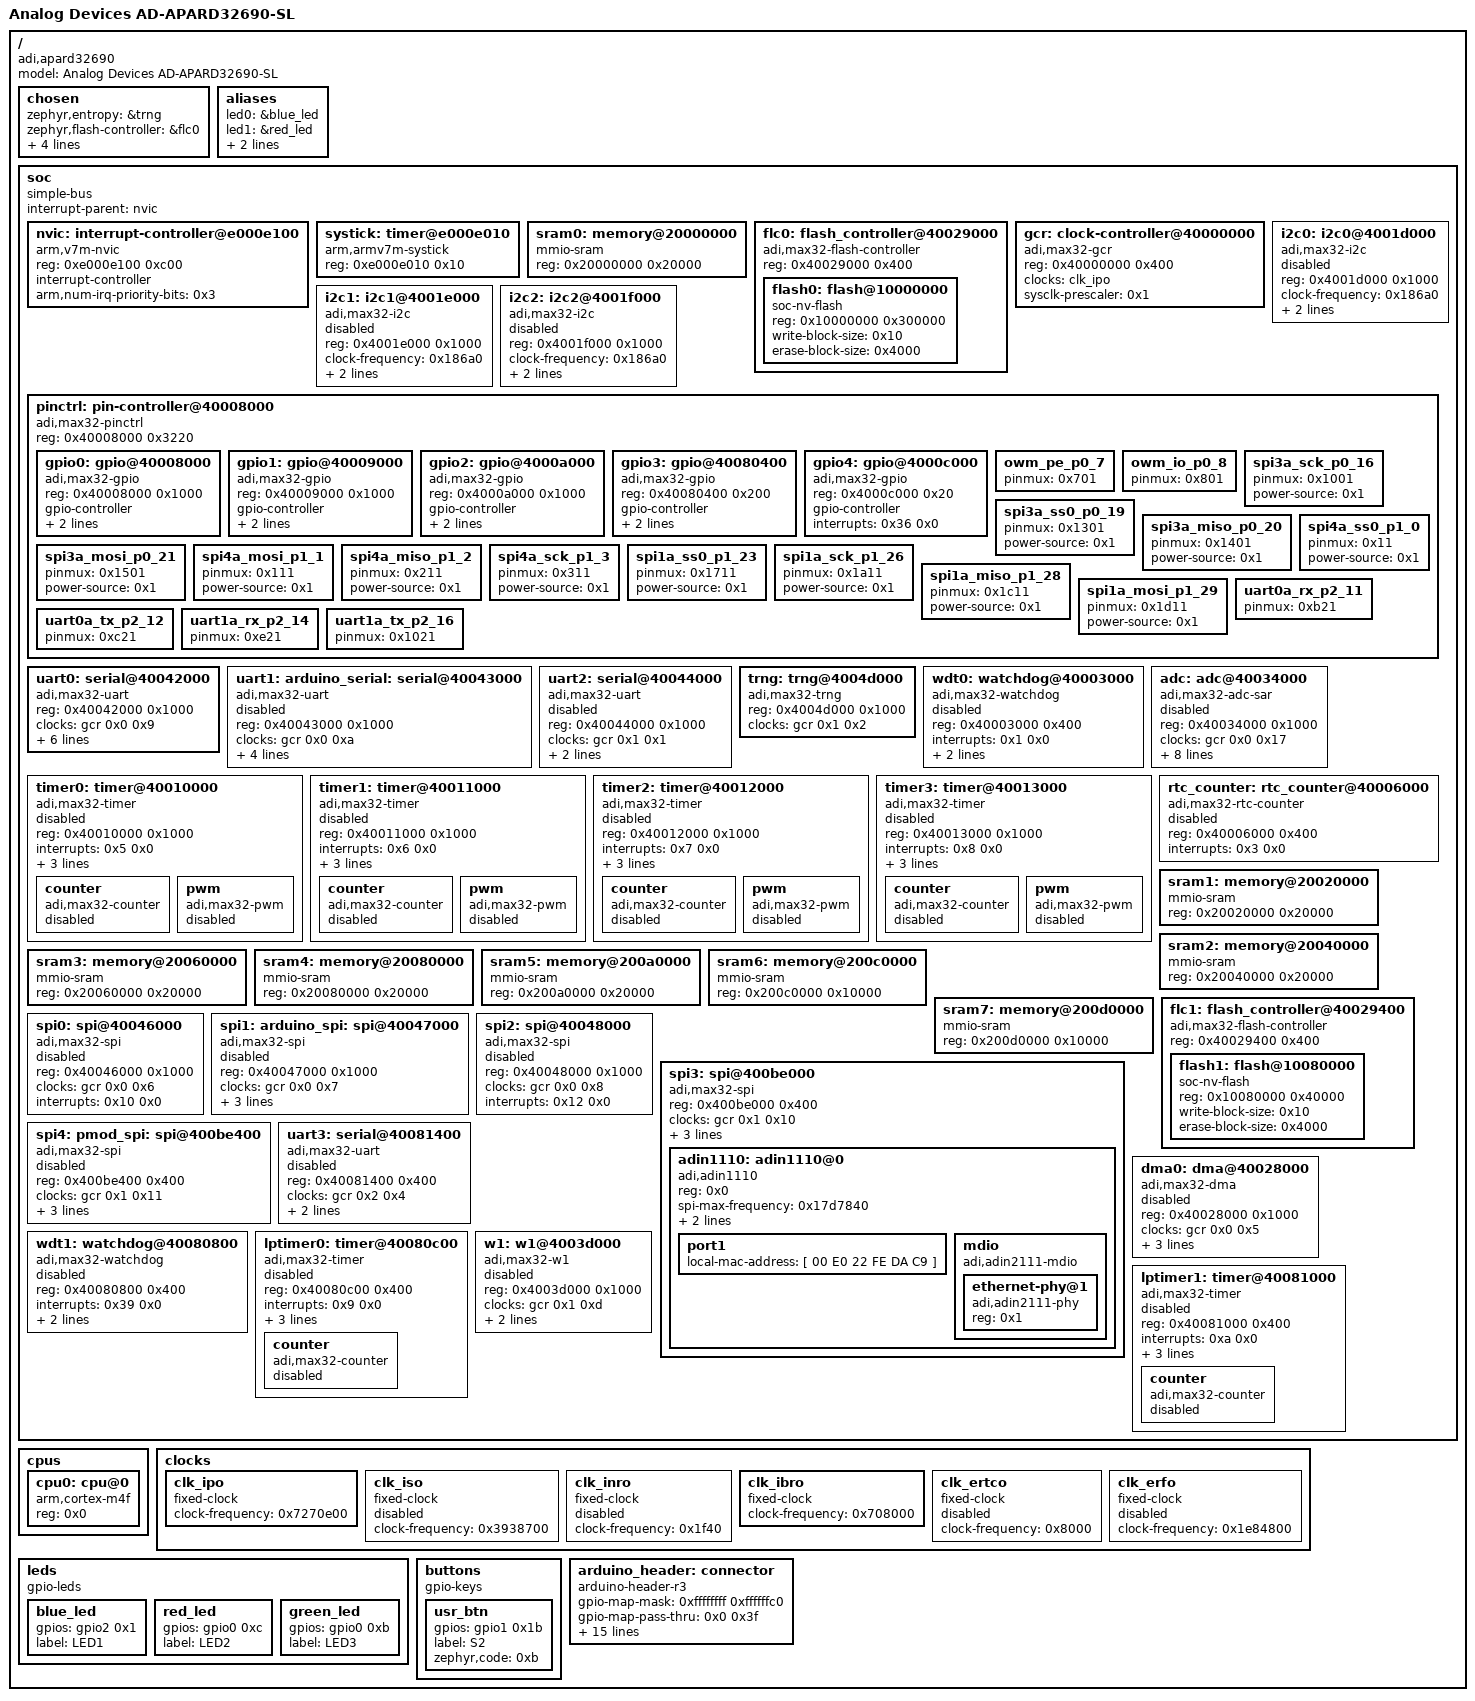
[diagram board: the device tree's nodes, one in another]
/dts-v1/;

/ {
	#address-cells = < 0x1 >;
	#size-cells = < 0x1 >;
	model = "Analog Devices AD-APARD32690-SL";
	compatible = "adi,apard32690";
	chosen {
		zephyr,entropy = &trng;
		zephyr,flash-controller = &flc0;
		zephyr,console = &uart0;
		zephyr,shell-uart = &uart0;
		zephyr,sram = &sram0;
		zephyr,flash = &flash0;
	};
	aliases {
		led0 = &blue_led;
		led1 = &red_led;
		led2 = &green_led;
		sw0 = &usr_btn;
	};
	soc {
		#address-cells = < 0x1 >;
		#size-cells = < 0x1 >;
		compatible = "simple-bus";
		interrupt-parent = < &nvic >;
		ranges;
		nvic: interrupt-controller@e000e100 {
			#address-cells = < 0x1 >;
			compatible = "arm,v7m-nvic";
			reg = < 0xe000e100 0xc00 >;
			interrupt-controller;
			#interrupt-cells = < 0x2 >;
			arm,num-irq-priority-bits = < 0x3 >;
			phandle = < 0x1 >;
		};
		systick: timer@e000e010 {
			compatible = "arm,armv7m-systick";
			reg = < 0xe000e010 0x10 >;
		};
		sram0: memory@20000000 {
			compatible = "mmio-sram";
			reg = < 0x20000000 0x20000 >;
		};
		flc0: flash_controller@40029000 {
			compatible = "adi,max32-flash-controller";
			reg = < 0x40029000 0x400 >;
			#address-cells = < 0x1 >;
			#size-cells = < 0x1 >;
			status = "okay";
			flash0: flash@10000000 {
				compatible = "soc-nv-flash";
				reg = < 0x10000000 0x300000 >;
				write-block-size = < 0x10 >;
				erase-block-size = < 0x4000 >;
			};
		};
		gcr: clock-controller@40000000 {
			reg = < 0x40000000 0x400 >;
			compatible = "adi,max32-gcr";
			#clock-cells = < 0x2 >;
			clocks = < &clk_ipo >;
			sysclk-prescaler = < 0x1 >;
			status = "okay";
			phandle = < 0x3 >;
		};
		i2c0: i2c0@4001d000 {
			compatible = "adi,max32-i2c";
			reg = < 0x4001d000 0x1000 >;
			#address-cells = < 0x1 >;
			#size-cells = < 0x0 >;
			clock-frequency = < 0x186a0 >;
			clocks = < &gcr 0x0 0xd >;
			interrupts = < 0xd 0x0 >;
			status = "disabled";
		};
		i2c1: i2c1@4001e000 {
			compatible = "adi,max32-i2c";
			reg = < 0x4001e000 0x1000 >;
			#address-cells = < 0x1 >;
			#size-cells = < 0x0 >;
			clock-frequency = < 0x186a0 >;
			clocks = < &gcr 0x0 0x1c >;
			interrupts = < 0x24 0x0 >;
			status = "disabled";
		};
		i2c2: i2c2@4001f000 {
			compatible = "adi,max32-i2c";
			reg = < 0x4001f000 0x1000 >;
			#address-cells = < 0x1 >;
			#size-cells = < 0x0 >;
			clock-frequency = < 0x186a0 >;
			clocks = < &gcr 0x1 0x18 >;
			interrupts = < 0x3e 0x0 >;
			status = "disabled";
		};
		pinctrl: pin-controller@40008000 {
			compatible = "adi,max32-pinctrl";
			#address-cells = < 0x1 >;
			#size-cells = < 0x1 >;
			reg = < 0x40008000 0x3220 >;
			gpio0: gpio@40008000 {
				reg = < 0x40008000 0x1000 >;
				compatible = "adi,max32-gpio";
				gpio-controller;
				#gpio-cells = < 0x2 >;
				clocks = < &gcr 0x0 0x0 >;
				interrupts = < 0x18 0x0 >;
				status = "okay";
				phandle = < 0x10 >;
			};
			gpio1: gpio@40009000 {
				reg = < 0x40009000 0x1000 >;
				compatible = "adi,max32-gpio";
				gpio-controller;
				#gpio-cells = < 0x2 >;
				interrupts = < 0x19 0x0 >;
				clocks = < &gcr 0x0 0x1 >;
				status = "okay";
				phandle = < 0x18 >;
			};
			gpio2: gpio@4000a000 {
				reg = < 0x4000a000 0x1000 >;
				compatible = "adi,max32-gpio";
				gpio-controller;
				#gpio-cells = < 0x2 >;
				interrupts = < 0x1a 0x0 >;
				clocks = < &gcr 0x0 0x2 >;
				status = "okay";
				phandle = < 0x17 >;
			};
			gpio3: gpio@40080400 {
				reg = < 0x40080400 0x200 >;
				compatible = "adi,max32-gpio";
				gpio-controller;
				#gpio-cells = < 0x2 >;
				interrupts = < 0x3a 0x0 >;
				clocks = < &gcr 0x2 0x0 >;
				status = "okay";
				phandle = < 0x19 >;
			};
			gpio4: gpio@4000c000 {
				reg = < 0x4000c000 0x20 >;
				compatible = "adi,max32-gpio";
				gpio-controller;
				#gpio-cells = < 0x2 >;
				interrupts = < 0x36 0x0 >;
				status = "okay";
			};
			owm_pe_p0_7: owm_pe_p0_7 {
				pinmux = < 0x701 >;
				phandle = < 0x16 >;
			};
			owm_io_p0_8: owm_io_p0_8 {
				pinmux = < 0x801 >;
				phandle = < 0x15 >;
			};
			spi3a_sck_p0_16: spi3a_sck_p0_16 {
				pinmux = < 0x1001 >;
				power-source = < 0x1 >;
				phandle = < 0xe >;
			};
			spi3a_ss0_p0_19: spi3a_ss0_p0_19 {
				pinmux = < 0x1301 >;
				power-source = < 0x1 >;
				phandle = < 0xf >;
			};
			spi3a_miso_p0_20: spi3a_miso_p0_20 {
				pinmux = < 0x1401 >;
				power-source = < 0x1 >;
				phandle = < 0xc >;
			};
			spi3a_mosi_p0_21: spi3a_mosi_p0_21 {
				pinmux = < 0x1501 >;
				power-source = < 0x1 >;
				phandle = < 0xd >;
			};
			spi4a_ss0_p1_0: spi4a_ss0_p1_0 {
				pinmux = < 0x11 >;
				power-source = < 0x1 >;
				phandle = < 0x14 >;
			};
			spi4a_mosi_p1_1: spi4a_mosi_p1_1 {
				pinmux = < 0x111 >;
				power-source = < 0x1 >;
				phandle = < 0x12 >;
			};
			spi4a_miso_p1_2: spi4a_miso_p1_2 {
				pinmux = < 0x211 >;
				power-source = < 0x1 >;
				phandle = < 0x11 >;
			};
			spi4a_sck_p1_3: spi4a_sck_p1_3 {
				pinmux = < 0x311 >;
				power-source = < 0x1 >;
				phandle = < 0x13 >;
			};
			spi1a_ss0_p1_23: spi1a_ss0_p1_23 {
				pinmux = < 0x1711 >;
				power-source = < 0x1 >;
				phandle = < 0xb >;
			};
			spi1a_sck_p1_26: spi1a_sck_p1_26 {
				pinmux = < 0x1a11 >;
				power-source = < 0x1 >;
				phandle = < 0xa >;
			};
			spi1a_miso_p1_28: spi1a_miso_p1_28 {
				pinmux = < 0x1c11 >;
				power-source = < 0x1 >;
				phandle = < 0x8 >;
			};
			spi1a_mosi_p1_29: spi1a_mosi_p1_29 {
				pinmux = < 0x1d11 >;
				power-source = < 0x1 >;
				phandle = < 0x9 >;
			};
			uart0a_rx_p2_11: uart0a_rx_p2_11 {
				pinmux = < 0xb21 >;
				phandle = < 0x5 >;
			};
			uart0a_tx_p2_12: uart0a_tx_p2_12 {
				pinmux = < 0xc21 >;
				phandle = < 0x4 >;
			};
			uart1a_rx_p2_14: uart1a_rx_p2_14 {
				pinmux = < 0xe21 >;
				phandle = < 0x7 >;
			};
			uart1a_tx_p2_16: uart1a_tx_p2_16 {
				pinmux = < 0x1021 >;
				phandle = < 0x6 >;
			};
		};
		uart0: serial@40042000 {
			compatible = "adi,max32-uart";
			reg = < 0x40042000 0x1000 >;
			clocks = < &gcr 0x0 0x9 >;
			clock-source = < 0x2 >;
			interrupts = < 0xe 0x0 >;
			status = "okay";
			pinctrl-0 = < &uart0a_tx_p2_12 &uart0a_rx_p2_11 >;
			pinctrl-names = "default";
			current-speed = < 0x1c200 >;
			data-bits = < 0x8 >;
			parity = "none";
		};
		uart1: arduino_serial: serial@40043000 {
			compatible = "adi,max32-uart";
			reg = < 0x40043000 0x1000 >;
			clocks = < &gcr 0x0 0xa >;
			clock-source = < 0x2 >;
			interrupts = < 0xf 0x0 >;
			status = "disabled";
			pinctrl-0 = < &uart1a_tx_p2_16 &uart1a_rx_p2_14 >;
			pinctrl-names = "default";
			current-speed = < 0x1c200 >;
		};
		uart2: serial@40044000 {
			compatible = "adi,max32-uart";
			reg = < 0x40044000 0x1000 >;
			clocks = < &gcr 0x1 0x1 >;
			clock-source = < 0x0 >;
			interrupts = < 0x22 0x0 >;
			status = "disabled";
		};
		trng: trng@4004d000 {
			compatible = "adi,max32-trng";
			reg = < 0x4004d000 0x1000 >;
			clocks = < &gcr 0x1 0x2 >;
			status = "okay";
		};
		wdt0: watchdog@40003000 {
			compatible = "adi,max32-watchdog";
			reg = < 0x40003000 0x400 >;
			interrupts = < 0x1 0x0 >;
			clocks = < &gcr 0x1 0x1b >;
			clock-source = < 0x0 >;
			status = "disabled";
		};
		adc: adc@40034000 {
			compatible = "adi,max32-adc-sar", "adi,max32-adc";
			reg = < 0x40034000 0x1000 >;
			clocks = < &gcr 0x0 0x17 >;
			channel-count = < 0x15 >;
			#io-channel-cells = < 0x1 >;
			interrupts = < 0x14 0x0 >;
			resolution = < 0xc >;
			vref-mv = < 0x4e2 >;
			status = "disabled";
			clock-source = < 0x0 >;
			clock-divider = < 0x10 >;
			track-count = < 0x4 >;
			idle-count = < 0x5 >;
		};
		timer0: timer@40010000 {
			compatible = "adi,max32-timer";
			reg = < 0x40010000 0x1000 >;
			interrupts = < 0x5 0x0 >;
			status = "disabled";
			clocks = < &gcr 0x0 0xf >;
			clock-source = < 0x0 >;
			prescaler = < 0x1 >;
			counter {
				compatible = "adi,max32-counter";
				status = "disabled";
			};
			pwm {
				compatible = "adi,max32-pwm";
				status = "disabled";
				#pwm-cells = < 0x3 >;
			};
		};
		timer1: timer@40011000 {
			compatible = "adi,max32-timer";
			reg = < 0x40011000 0x1000 >;
			interrupts = < 0x6 0x0 >;
			status = "disabled";
			clocks = < &gcr 0x0 0x10 >;
			clock-source = < 0x0 >;
			prescaler = < 0x1 >;
			counter {
				compatible = "adi,max32-counter";
				status = "disabled";
			};
			pwm {
				compatible = "adi,max32-pwm";
				status = "disabled";
				#pwm-cells = < 0x3 >;
			};
		};
		timer2: timer@40012000 {
			compatible = "adi,max32-timer";
			reg = < 0x40012000 0x1000 >;
			interrupts = < 0x7 0x0 >;
			status = "disabled";
			clocks = < &gcr 0x0 0x11 >;
			clock-source = < 0x0 >;
			prescaler = < 0x1 >;
			counter {
				compatible = "adi,max32-counter";
				status = "disabled";
			};
			pwm {
				compatible = "adi,max32-pwm";
				status = "disabled";
				#pwm-cells = < 0x3 >;
			};
		};
		timer3: timer@40013000 {
			compatible = "adi,max32-timer";
			reg = < 0x40013000 0x1000 >;
			interrupts = < 0x8 0x0 >;
			status = "disabled";
			clocks = < &gcr 0x0 0x12 >;
			clock-source = < 0x0 >;
			prescaler = < 0x1 >;
			counter {
				compatible = "adi,max32-counter";
				status = "disabled";
			};
			pwm {
				compatible = "adi,max32-pwm";
				status = "disabled";
				#pwm-cells = < 0x3 >;
			};
		};
		rtc_counter: rtc_counter@40006000 {
			compatible = "adi,max32-rtc-counter";
			reg = < 0x40006000 0x400 >;
			interrupts = < 0x3 0x0 >;
			status = "disabled";
		};
		sram1: memory@20020000 {
			compatible = "mmio-sram";
			reg = < 0x20020000 0x20000 >;
		};
		sram2: memory@20040000 {
			compatible = "mmio-sram";
			reg = < 0x20040000 0x20000 >;
		};
		sram3: memory@20060000 {
			compatible = "mmio-sram";
			reg = < 0x20060000 0x20000 >;
		};
		sram4: memory@20080000 {
			compatible = "mmio-sram";
			reg = < 0x20080000 0x20000 >;
		};
		sram5: memory@200a0000 {
			compatible = "mmio-sram";
			reg = < 0x200a0000 0x20000 >;
		};
		sram6: memory@200c0000 {
			compatible = "mmio-sram";
			reg = < 0x200c0000 0x10000 >;
		};
		sram7: memory@200d0000 {
			compatible = "mmio-sram";
			reg = < 0x200d0000 0x10000 >;
		};
		flc1: flash_controller@40029400 {
			compatible = "adi,max32-flash-controller";
			reg = < 0x40029400 0x400 >;
			#address-cells = < 0x1 >;
			#size-cells = < 0x1 >;
			status = "okay";
			flash1: flash@10080000 {
				compatible = "soc-nv-flash";
				reg = < 0x10080000 0x40000 >;
				write-block-size = < 0x10 >;
				erase-block-size = < 0x4000 >;
			};
		};
		spi0: spi@40046000 {
			compatible = "adi,max32-spi";
			reg = < 0x40046000 0x1000 >;
			#address-cells = < 0x1 >;
			#size-cells = < 0x0 >;
			clocks = < &gcr 0x0 0x6 >;
			interrupts = < 0x10 0x0 >;
			status = "disabled";
		};
		spi1: arduino_spi: spi@40047000 {
			compatible = "adi,max32-spi";
			reg = < 0x40047000 0x1000 >;
			#address-cells = < 0x1 >;
			#size-cells = < 0x0 >;
			clocks = < &gcr 0x0 0x7 >;
			interrupts = < 0x11 0x0 >;
			status = "disabled";
			pinctrl-0 = < &spi1a_miso_p1_28 &spi1a_mosi_p1_29 &spi1a_sck_p1_26 &spi1a_ss0_p1_23 >;
			pinctrl-names = "default";
		};
		spi2: spi@40048000 {
			compatible = "adi,max32-spi";
			reg = < 0x40048000 0x1000 >;
			#address-cells = < 0x1 >;
			#size-cells = < 0x0 >;
			clocks = < &gcr 0x0 0x8 >;
			interrupts = < 0x12 0x0 >;
			status = "disabled";
		};
		spi3: spi@400be000 {
			compatible = "adi,max32-spi";
			reg = < 0x400be000 0x400 >;
			#address-cells = < 0x1 >;
			#size-cells = < 0x0 >;
			clocks = < &gcr 0x1 0x10 >;
			interrupts = < 0x38 0x0 >;
			status = "okay";
			pinctrl-0 = < &spi3a_miso_p0_20 &spi3a_mosi_p0_21 &spi3a_sck_p0_16 &spi3a_ss0_p0_19 >;
			pinctrl-names = "default";
			adin1110: adin1110@0 {
				compatible = "adi,adin1110";
				reg = < 0x0 >;
				spi-max-frequency = < 0x17d7840 >;
				int-gpios = < &gpio0 0x11 0x101 >;
				reset-gpios = < &gpio0 0xf 0x101 >;
				status = "okay";
				port1 {
					local-mac-address = [ 00 E0 22 FE DA C9 ];
				};
				mdio {
					compatible = "adi,adin2111-mdio";
					#address-cells = < 0x1 >;
					#size-cells = < 0x0 >;
					ethernet-phy@1 {
						reg = < 0x1 >;
						compatible = "adi,adin2111-phy";
					};
				};
			};
		};
		spi4: pmod_spi: spi@400be400 {
			compatible = "adi,max32-spi";
			reg = < 0x400be400 0x400 >;
			#address-cells = < 0x1 >;
			#size-cells = < 0x0 >;
			clocks = < &gcr 0x1 0x11 >;
			interrupts = < 0x69 0x0 >;
			status = "disabled";
			pinctrl-0 = < &spi4a_miso_p1_2 &spi4a_mosi_p1_1 &spi4a_sck_p1_3 &spi4a_ss0_p1_0 >;
			pinctrl-names = "default";
		};
		uart3: serial@40081400 {
			compatible = "adi,max32-uart";
			reg = < 0x40081400 0x400 >;
			clocks = < &gcr 0x2 0x4 >;
			clock-source = < 0x2 >;
			interrupts = < 0x58 0x0 >;
			status = "disabled";
		};
		dma0: dma@40028000 {
			compatible = "adi,max32-dma";
			reg = < 0x40028000 0x1000 >;
			clocks = < &gcr 0x0 0x5 >;
			interrupts = < 0x1c 0x0 >, < 0x1d 0x0 >, < 0x1e 0x0 >, < 0x1f 0x0 >;
			dma-channels = < 0x10 >;
			status = "disabled";
			#dma-cells = < 0x2 >;
		};
		wdt1: watchdog@40080800 {
			compatible = "adi,max32-watchdog";
			reg = < 0x40080800 0x400 >;
			interrupts = < 0x39 0x0 >;
			clocks = < &gcr 0x2 0x1 >;
			clock-source = < 0x2 >;
			status = "disabled";
		};
		lptimer0: timer@40080c00 {
			compatible = "adi,max32-timer";
			reg = < 0x40080c00 0x400 >;
			interrupts = < 0x9 0x0 >;
			status = "disabled";
			clocks = < &gcr 0x2 0x2 >;
			clock-source = < 0x2 >;
			prescaler = < 0x1 >;
			counter {
				compatible = "adi,max32-counter";
				status = "disabled";
			};
		};
		lptimer1: timer@40081000 {
			compatible = "adi,max32-timer";
			reg = < 0x40081000 0x400 >;
			interrupts = < 0xa 0x0 >;
			status = "disabled";
			clocks = < &gcr 0x2 0x3 >;
			clock-source = < 0x2 >;
			prescaler = < 0x1 >;
			counter {
				compatible = "adi,max32-counter";
				status = "disabled";
			};
		};
		w1: w1@4003d000 {
			compatible = "adi,max32-w1";
			reg = < 0x4003d000 0x1000 >;
			clocks = < &gcr 0x1 0xd >;
			interrupts = < 0x43 0x0 >;
			status = "disabled";
			pinctrl-0 = < &owm_io_p0_8 &owm_pe_p0_7 >;
			pinctrl-names = "default";
		};
	};
	cpus {
		#address-cells = < 0x1 >;
		#size-cells = < 0x0 >;
		cpu0: cpu@0 {
			device_type = "cpu";
			compatible = "arm,cortex-m4f";
			reg = < 0x0 >;
		};
	};
	clocks {
		clk_ipo: clk_ipo {
			compatible = "fixed-clock";
			#clock-cells = < 0x0 >;
			clock-frequency = < 0x7270e00 >;
			status = "okay";
			phandle = < 0x2 >;
		};
		clk_iso: clk_iso {
			compatible = "fixed-clock";
			#clock-cells = < 0x0 >;
			clock-frequency = < 0x3938700 >;
			status = "disabled";
		};
		clk_inro: clk_inro {
			compatible = "fixed-clock";
			#clock-cells = < 0x0 >;
			clock-frequency = < 0x1f40 >;
			status = "disabled";
		};
		clk_ibro: clk_ibro {
			compatible = "fixed-clock";
			#clock-cells = < 0x0 >;
			clock-frequency = < 0x708000 >;
			status = "okay";
		};
		clk_ertco: clk_ertco {
			compatible = "fixed-clock";
			#clock-cells = < 0x0 >;
			clock-frequency = < 0x8000 >;
			status = "disabled";
		};
		clk_erfo: clk_erfo {
			compatible = "fixed-clock";
			#clock-cells = < 0x0 >;
			clock-frequency = < 0x1e84800 >;
			status = "disabled";
		};
	};
	leds {
		compatible = "gpio-leds";
		blue_led: blue_led {
			gpios = < &gpio2 0x1 0x0 >;
			label = "LED1";
		};
		red_led: red_led {
			gpios = < &gpio0 0xc 0x0 >;
			label = "LED2";
		};
		green_led: green_led {
			gpios = < &gpio0 0xb 0x0 >;
			label = "LED3";
		};
	};
	buttons {
		compatible = "gpio-keys";
		usr_btn: usr_btn {
			gpios = < &gpio1 0x1b 0x20 >;
			label = "S2";
			zephyr,code = < 0xb >;
		};
	};
	arduino_header: connector {
		compatible = "arduino-header-r3";
		#gpio-cells = < 0x2 >;
		gpio-map-mask = < 0xffffffff 0xffffffc0 >;
		gpio-map-pass-thru = < 0x0 0x3f >;
		gpio-map = < 0x0 0x0 &gpio3 0x0 0x0 >, < 0x1 0x0 &gpio3 0x1 0x0 >, < 0x2 0x0 &gpio3 0x2 0x0 >, < 0x3 0x0 &gpio3 0x3 0x0 >, < 0x4 0x0 &gpio3 0x4 0x0 >, < 0x5 0x0 &gpio3 0x5 0x0 >, < 0x6 0x0 &gpio2 0xe 0x0 >, < 0x7 0x0 &gpio2 0x10 0x0 >, < 0x8 0x0 &gpio2 0xd 0x0 >, < 0x9 0x0 &gpio2 0xf 0x0 >, < 0xa 0x0 &gpio0 0x8 0x0 >, < 0xb 0x0 &gpio0 0x7 0x0 >, < 0xc 0x0 &gpio1 0x18 0x0 >, < 0xd 0x0 &gpio1 0x19 0x0 >, < 0xe 0x0 &gpio1 0x1f 0x0 >, < 0xf 0x0 &gpio1 0x1e 0x0 >, < 0x10 0x0 &gpio1 0x17 0x0 >, < 0x11 0x0 &gpio1 0x1d 0x0 >, < 0x12 0x0 &gpio1 0x1c 0x0 >, < 0x13 0x0 &gpio1 0x1a 0x0 >, < 0x14 0x0 &gpio2 0x11 0x0 >, < 0x15 0x0 &gpio2 0x12 0x0 >;
	};
};
